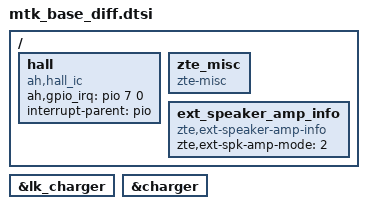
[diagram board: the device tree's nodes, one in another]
/*
 * when you want to delete some nodes or property, modify this dtsi.
 * some diff between mtk and zte muses.
 */

#include "../bat_setting/battery_protect_policy_080509200080.dtsi"

/{
	hall: hall {
		compatible = "ah,hall_ic";
		status="okay";
		ah,gpio_irq = <&pio 7 0>;
		interrupt-parent = <&pio>;
	};

	zte_misc: zte_misc {
		status="okay";
		compatible = "zte-misc";
	};

	ext_speaker_amp_info {
		status="okay";
		compatible = "zte,ext-speaker-amp-info";
		zte,ext-spk-amp-mode = <2>;
	};
};

&lk_charger {
	/delete-property/ enable_pe_plus;
};

&charger {
	/delete-property/ enable_pe_plus;
	/delete-property/ enable_pe_2;
	/delete-property/ enable_pe_3;
	/delete-property/ enable_pe_4;
	/delete-property/ enable_type_c;
};
